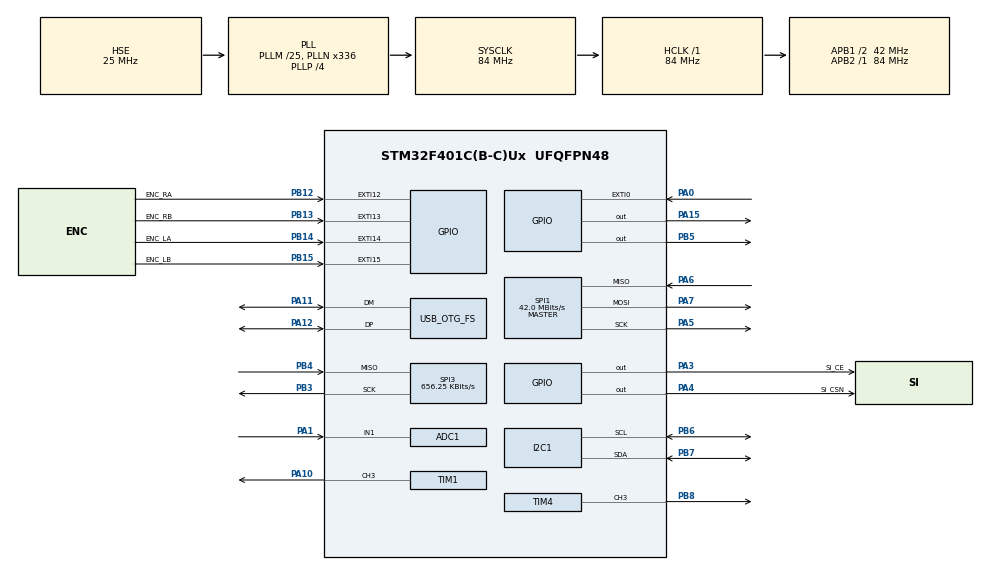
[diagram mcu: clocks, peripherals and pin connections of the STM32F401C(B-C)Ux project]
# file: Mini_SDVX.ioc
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ADC1.Channel-1\#ChannelRegularConversion=ADC_CHANNEL_1
ADC1.NbrOfConversionFlag=1
ADC1.Rank-1\#ChannelRegularConversion=1
ADC1.SamplingTime-1\#ChannelRegularConversion=ADC_SAMPLETIME_3CYCLES
ADC1.master=1
AL94.I-CUBE-USBD-COMPOSITE.1.0.3.CompositeCcUSBJjCOMPOSITEJjCDCIiACM=true
AL94.I-CUBE-USBD-COMPOSITE.1.0.3.CompositeCcUSBJjCOMPOSITEJjCOMPOSITE=true
AL94.I-CUBE-USBD-COMPOSITE.1.0.3.CompositeCcUSBJjCOMPOSITEJjCore=true
AL94.I-CUBE-USBD-COMPOSITE.1.0.3.CompositeCcUSBJjCOMPOSITEJjHIDIiKEYBOARD=true
AL94.I-CUBE-USBD-COMPOSITE.1.0.3.CompositeCcUSBJjCOMPOSITEJjHIDIiMOUSE=true
AL94.I-CUBE-USBD-COMPOSITE.1.0.3._STM32F1_DEVICE=false
AL94.I-CUBE-USBD-COMPOSITE.1.0.3._USBD_USE_CDC_ACM=true
AL94.I-CUBE-USBD-COMPOSITE.1.0.3._USBD_USE_DFU=false
AL94.I-CUBE-USBD-COMPOSITE.1.0.3._USBD_USE_HID_CUSTOM=false
AL94.I-CUBE-USBD-COMPOSITE.1.0.3._USBD_USE_HID_KEYBOARD=true
AL94.I-CUBE-USBD-COMPOSITE.1.0.3._USBD_USE_HID_MOUSE=true
AL94.I-CUBE-USBD-COMPOSITE.1.0.3._USBD_USE_HS=false
Dma.Request0=TIM4_CH3
Dma.Request1=TIM1_CH3
Dma.TIM1_CH3.1.Direction=DMA_MEMORY_TO_PERIPH
Dma.TIM1_CH3.1.FIFOMode=DMA_FIFOMODE_DISABLE
Dma.TIM1_CH3.1.Instance=DMA2_Stream6
Dma.TIM1_CH3.1.MemDataAlignment=DMA_MDATAALIGN_HALFWORD
Dma.TIM1_CH3.1.MemInc=DMA_MINC_ENABLE
Dma.TIM1_CH3.1.Mode=DMA_CIRCULAR
Dma.TIM1_CH3.1.PeriphDataAlignment=DMA_PDATAALIGN_HALFWORD
Dma.TIM1_CH3.1.PeriphInc=DMA_PINC_DISABLE
Dma.TIM1_CH3.1.Priority=DMA_PRIORITY_LOW
Dma.TIM4_CH3.0.Direction=DMA_MEMORY_TO_PERIPH
Dma.TIM4_CH3.0.FIFOMode=DMA_FIFOMODE_DISABLE
Dma.TIM4_CH3.0.Instance=DMA1_Stream7
Dma.TIM4_CH3.0.MemDataAlignment=DMA_MDATAALIGN_HALFWORD
Dma.TIM4_CH3.0.MemInc=DMA_MINC_ENABLE
Dma.TIM4_CH3.0.Mode=DMA_CIRCULAR
Dma.TIM4_CH3.0.PeriphDataAlignment=DMA_PDATAALIGN_HALFWORD
Dma.TIM4_CH3.0.PeriphInc=DMA_PINC_DISABLE
Dma.TIM4_CH3.0.Priority=DMA_PRIORITY_LOW
Mcu.Family=STM32F4
Mcu.Name=STM32F401C(B-C)Ux
Mcu.Package=UFQFPN48
NVIC.DMA1_Stream7_IRQn=true\:0\:0\:false\:false\:true\:false\:true\:true
NVIC.DMA2_Stream6_IRQn=true\:0\:0\:false\:false\:true\:false\:true\:true
NVIC.EXTI0_IRQn=true\:14\:0\:true\:false\:true\:true\:true\:true
NVIC.EXTI15_10_IRQn=true\:5\:0\:true\:false\:true\:true\:true\:true
NVIC.OTG_FS_IRQn=true\:5\:0\:true\:false\:true\:true\:true\:true
NVIC.PriorityGroup=NVIC_PRIORITYGROUP_4
NVIC.TIM3_IRQn=true\:10\:0\:true\:false\:true\:true\:true\:true
NVIC.TIM5_IRQn=true\:0\:0\:true\:false\:true\:true\:true\:true
PA0-WKUP.GPIO_ModeDefaultEXTI=GPIO_MODE_IT_RISING_FALLING
PA0-WKUP.GPIO_PuPd=GPIO_PULLUP
PA0-WKUP.Signal=GPXTI0
PA1.Signal=ADCx_IN1
PA10.Signal=S_TIM1_CH3
PA11.Mode=Device_Only
PA11.Signal=USB_OTG_FS_DM
PA12.Mode=Device_Only
PA12.Signal=USB_OTG_FS_DP
PA13.Mode=Serial_Wire
PA13.Signal=SYS_JTMS-SWDIO
PA14.Mode=Serial_Wire
PA14.Signal=SYS_JTCK-SWCLK
PA15.Signal=GPIO_Output
PA3.GPIO_Label=Si_CE
PA3.Signal=GPIO_Output
PA4.GPIO_Label=Si_CSN
PA4.Signal=GPIO_Output
PA5.Mode=Full_Duplex_Master
PA5.Signal=SPI1_SCK
PA6.Mode=Full_Duplex_Master
PA6.Signal=SPI1_MISO
PA7.Mode=Full_Duplex_Master
PA7.Signal=SPI1_MOSI
PB12.GPIO_Label=ENC_RA
PB12.GPIO_ModeDefaultEXTI=GPIO_MODE_IT_RISING_FALLING
PB12.GPIO_PuPd=GPIO_PULLUP
PB12.Signal=GPXTI12
PB13.GPIO_Label=ENC_RB
PB13.GPIO_ModeDefaultEXTI=GPIO_MODE_IT_RISING_FALLING
PB13.GPIO_PuPd=GPIO_PULLUP
PB13.Signal=GPXTI13
PB14.GPIO_Label=ENC_LA
PB14.GPIO_ModeDefaultEXTI=GPIO_MODE_IT_RISING_FALLING
PB14.GPIO_PuPd=GPIO_PULLUP
PB14.Signal=GPXTI14
PB15.GPIO_Label=ENC_LB
PB15.GPIO_ModeDefaultEXTI=GPIO_MODE_IT_RISING_FALLING
PB15.GPIO_PuPd=GPIO_PULLUP
PB15.Signal=GPXTI15
PB3.Mode=RX_Only_Simplex_Unidirect_Master
PB3.Signal=SPI3_SCK
PB4.Mode=RX_Only_Simplex_Unidirect_Master
PB4.Signal=SPI3_MISO
PB5.Signal=GPIO_Output
PB6.Mode=I2C
PB6.Signal=I2C1_SCL
PB7.Mode=I2C
PB7.Signal=I2C1_SDA
PB8.GPIO_Speed=GPIO_SPEED_FREQ_HIGH
PB8.Signal=S_TIM4_CH3
PH0\ -\ OSC_IN.Mode=HSE-External-Oscillator
PH0\ -\ OSC_IN.Signal=RCC_OSC_IN
PH1\ -\ OSC_OUT.Mode=HSE-External-Oscillator
PH1\ -\ OSC_OUT.Signal=RCC_OSC_OUT
ProjectManager.HeapSize=0x400
ProjectManager.StackSize=0x400
ProjectManager.TargetToolchain=SW4STM32
RCC.48MHZClocksFreq_Value=48000000
RCC.AHBFreq_Value=84000000
RCC.APB1CLKDivider=RCC_HCLK_DIV2
RCC.APB1Freq_Value=42000000
RCC.APB1TimFreq_Value=84000000
RCC.APB2Freq_Value=84000000
RCC.APB2TimFreq_Value=84000000
RCC.CortexFreq_Value=84000000
RCC.EnbaleCSS=true
RCC.HCLKFreq_Value=84000000
RCC.HSE_VALUE=25000000
RCC.HSI_VALUE=16000000
RCC.LSE_VALUE=32768
RCC.PLLM=25
RCC.PLLN=336
RCC.PLLP=RCC_PLLP_DIV4
RCC.PLLQ=7
RCC.SYSCLKFreq_VALUE=84000000
RCC.SYSCLKSource=RCC_SYSCLKSOURCE_PLLCLK
RCC.VCOOutputFreq_Value=336000000
SH.ADCx_IN1.0=ADC1_IN1,IN1
SH.S_TIM1_CH3.0=TIM1_CH3,PWM Generation3 CH3
SH.S_TIM4_CH3.0=TIM4_CH3,PWM Generation3 CH3
SPI1.CLKPhase=SPI_PHASE_1EDGE
SPI1.CLKPolarity=SPI_POLARITY_HIGH
SPI1.CalculateBaudRate=42.0 MBits/s
SPI1.Direction=SPI_DIRECTION_2LINES
SPI1.Mode=SPI_MODE_MASTER
SPI1.VirtualType=VM_MASTER
SPI3.BaudRatePrescaler=SPI_BAUDRATEPRESCALER_64
SPI3.CLKPhase=SPI_PHASE_1EDGE
SPI3.CLKPolarity=SPI_POLARITY_HIGH
SPI3.CalculateBaudRate=656.25 KBits/s
SPI3.Direction=SPI_DIRECTION_2LINES_RXONLY
SPI3.Mode=SPI_MODE_MASTER
SPI3.VirtualType=VM_MASTER
TIM1.Channel-PWM\ Generation3\ CH3=TIM_CHANNEL_3
TIM1.Period=104
TIM1.Prescaler=0
TIM3.AutoReloadPreload=TIM_AUTORELOAD_PRELOAD_DISABLE
TIM3.Period=999
TIM3.Prescaler=83
TIM4.AutoReloadPreload=TIM_AUTORELOAD_PRELOAD_DISABLE
TIM4.Channel-PWM\ Generation3\ CH3=TIM_CHANNEL_3
TIM4.OCPolarity_3=TIM_OCPOLARITY_HIGH
TIM4.Period=104
TIM4.Prescaler=0
TIM5.AutoReloadPreload=TIM_AUTORELOAD_PRELOAD_DISABLE
TIM5.Period=999
TIM5.Prescaler=83
USB_OTG_FS.VirtualMode=Device_Only
USB_OTG_FS.low_power_enable=DISABLE
VP_AL94.I-CUBE-USBD-COMPOSITE_VS_USBJjComposite_1.0.0_1.0.3.Mode=USBJjComposite
VP_TIM1_VS_ClockSourceINT.Mode=Internal
VP_TIM3_VS_ClockSourceINT.Mode=Internal
VP_TIM5_VS_ClockSourceINT.Mode=Internal
board=custom

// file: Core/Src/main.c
/* USER CODE BEGIN Header */
/**
 ******************************************************************************
 * @file           : main.c
 * @brief          : Main program body
 * @author         : MiTuan
 ******************************************************************************
 * @attention
 *
 * Copyright (c) 2022 MiTuan.
 * All rights reserved.
 *
 * This software is licensed under terms that can be found in the LICENSE file
 * in the root directory of this software component.
 * If no LICENSE file comes with this software, it is provided AS-IS.
 *
 ******************************************************************************
 */
/* USER CODE END Header */
#include "main.h"
#include "adc.h"
#include "dma.h"
#include "i2c.h"
#include "spi.h"
#include "tim.h"
#include "usb_otg.h"
#include "gpio.h"

/* USER CODE BEGIN Includes */
#include "usb_device.h"
//#include "usbd_cdc_acm.h"
#include "bsp.h"
#include "bsp_rgb.h"
/* USER CODE END Includes */

/* USER CODE BEGIN PD */
extern USBD_HandleTypeDef hUsbDevice;
/* USER CODE END PD */

void SystemClock_Config(void);

/* USER CODE BEGIN 0 */
//void debug(uint8_t *c, uint32_t len)
//{
//  USBD_CDC_SetTxBuffer(0, &hUsbDevice, c, len);
//  USBD_CDC_TransmitPacket(0, &hUsbDevice);
//}
/* USER CODE END 0 */

int main(void)
{

  /* MCU Configuration--------------------------------------------------------*/

  /* Reset of all peripherals, Initializes the Flash interface and the Systick. */
  HAL_Init();

  /* Configure the system clock */
  SystemClock_Config();

  /* Initialize all configured peripherals */
  MX_GPIO_Init();
  MX_ADC1_Init();
  MX_SPI1_Init();
  MX_DMA_Init();
  MX_TIM4_Init();
  MX_TIM1_Init();
  MX_SPI3_Init();
  MX_USB_OTG_FS_PCD_Init();
  MX_I2C1_Init();
  MX_TIM3_Init();
  MX_TIM5_Init();
  /* USER CODE BEGIN 2 */
  MX_USB_DEVICE_Init();
  HAL_TIM_Base_Start_IT(&htim3);

  bspInit();
  // AT24CXX_Init();
  /* USER CODE END 2 */

  /* Infinite loop */
  /* USER CODE BEGIN WHILE */
  while (1)
  {
    //WS_CloseAll();
    // HAL_Delay(500);
    // WS_WriteAll_RGB(100, 0, 100);
    // HAL_Delay(500);
    // USBD_CDC_SetTxBuffer(0, &hUsbDevice, (uint8_t *)"RGB SEND", 9);
    // USBD_CDC_TransmitPacket(0, &hUsbDevice);
    blinkWithKey(5);
    //soloShow(100);
    /* USER CODE END WHILE */

  }
}

void SystemClock_Config(void)
{
  RCC_OscInitTypeDef RCC_OscInitStruct = {0};
  RCC_ClkInitTypeDef RCC_ClkInitStruct = {0};

  /** Configure the main internal regulator output voltage
  */
  __HAL_RCC_PWR_CLK_ENABLE();
  __HAL_PWR_VOLTAGESCALING_CONFIG(PWR_REGULATOR_VOLTAGE_SCALE2);

  /** Initializes the RCC Oscillators according to the specified parameters
  * in the RCC_OscInitTypeDef structure.
  */
  RCC_OscInitStruct.OscillatorType = RCC_OSCILLATORTYPE_HSE;
  RCC_OscInitStruct.HSEState = RCC_HSE_ON;
  RCC_OscInitStruct.PLL.PLLState = RCC_PLL_ON;
  RCC_OscInitStruct.PLL.PLLSource = RCC_PLLSOURCE_HSE;
  RCC_OscInitStruct.PLL.PLLM = 25;
  RCC_OscInitStruct.PLL.PLLN = 336;
  RCC_OscInitStruct.PLL.PLLP = RCC_PLLP_DIV4;
  RCC_OscInitStruct.PLL.PLLQ = 7;
  if (HAL_RCC_OscConfig(&RCC_OscInitStruct) != HAL_OK)
  {
    Error_Handler();
  }

  /** Initializes the CPU, AHB and APB buses clocks
  */
  RCC_ClkInitStruct.ClockType = RCC_CLOCKTYPE_HCLK|RCC_CLOCKTYPE_SYSCLK
                              |RCC_CLOCKTYPE_PCLK1|RCC_CLOCKTYPE_PCLK2;
  RCC_ClkInitStruct.SYSCLKSource = RCC_SYSCLKSOURCE_PLLCLK;
  RCC_ClkInitStruct.AHBCLKDivider = RCC_SYSCLK_DIV1;
  RCC_ClkInitStruct.APB1CLKDivider = RCC_HCLK_DIV2;
  RCC_ClkInitStruct.APB2CLKDivider = RCC_HCLK_DIV1;

  if (HAL_RCC_ClockConfig(&RCC_ClkInitStruct, FLASH_LATENCY_2) != HAL_OK)
  {
    Error_Handler();
  }

  /** Enables the Clock Security System
  */
  HAL_RCC_EnableCSS();
}

void Error_Handler(void)
{
  __disable_irq();
  while (1)
  {
  }
}
